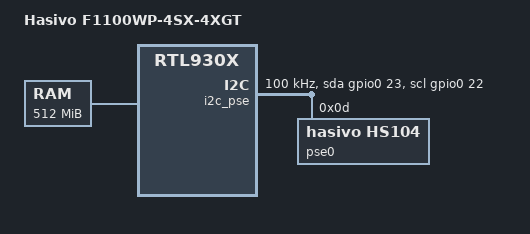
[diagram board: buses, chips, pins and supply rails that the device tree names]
// SPDX-License-Identifier: GPL-2.0-or-later
/dts-v1/;

#include "rtl9303_hasivo_f1100w-4sx-4xgt-common.dtsi"

/ {
	compatible = "hasivo,f1100wp-4sx-4xgt", "realtek,rtl930x-soc";
	model = "Hasivo F1100WP-4SX-4XGT";

	memory@0 {
		reg = <0x00000000 0x10000000>, /* 256 MiB lowmem */
		      <0x20000000 0x10000000>; /* 256 MiB highmem */
	};

	/*
	 * PoE/LED I2C bus. i2cdetect proved three devices at 0x0d (HS104
	 * PSE), 0x4d (STC8 LED MFD) and 0x50 (EEPROM). Note SCL/SDA are the
	 * reverse of the sibling s1100wp-8gt-se: SCL=gpio22, SDA=gpio23.
	 */
	i2c_pse: i2c-gpio {
		compatible = "i2c-gpio";
		#address-cells = <1>;
		#size-cells = <0>;

		scl-gpios = <&gpio0 22 (GPIO_ACTIVE_HIGH | GPIO_OPEN_DRAIN)>;
		sda-gpios = <&gpio0 23 (GPIO_ACTIVE_HIGH | GPIO_OPEN_DRAIN)>;
		clock-frequency = <100000>;
		status = "okay";

		pse0: pse0@d {
			compatible = "hasivo,hs104";
			reg = <0x0d>;
			#pse-cells = <1>;
			led-poll-interval-ms = <500>;
			hasivo,poe-led-i2c-addr = <0x4d>;
			hasivo,poe-led-reg = <0x01>;
			hasivo,poe-led-execute-bit = <0x40>;
			hasivo,poe-led-masks = <0x08 0x04 0x02 0x01>;
			status = "okay";

			/*
			 * HS104PTI variant: 1x 802.3bt/HiPoE + 3x 802.3at.
			 * PI 0 -> lan5 (HiPoE 90W), PI 1..3 -> lan6..8 (AT 30W).
			 * Values map to the driver's PROTOCOL register encoding:
			 *   <=15.4W=AF, <=30W=AT, <=60W=BT, <=90W=HiPoE.
			 */
			hasivo,port-max-power-mw = <90000 30000 30000 30000>;
		};
	};
};

&phy24 { pses = <&pse0 0>; };
&phy25 { pses = <&pse0 1>; };
&phy26 { pses = <&pse0 2>; };
&phy27 { pses = <&pse0 3>; };
